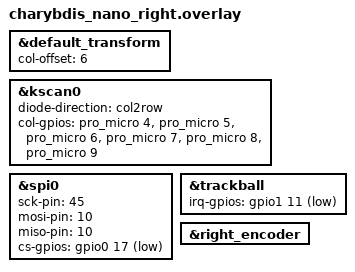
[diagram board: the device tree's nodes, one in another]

 
#include "charybdis_nano.dtsi"

&default_transform {
    col-offset = <6>;
};

&kscan0 {
    diode-direction = "col2row";
    col-gpios
        = <&pro_micro 4 (GPIO_ACTIVE_HIGH)> // COL0 
        , <&pro_micro 5 (GPIO_ACTIVE_HIGH)> // COL1 
        , <&pro_micro 6 (GPIO_ACTIVE_HIGH)> // COL2 
        , <&pro_micro 7 (GPIO_ACTIVE_HIGH)> // COL3 
	, <&pro_micro 8 (GPIO_ACTIVE_HIGH)> // COL1 
        , <&pro_micro 9 (GPIO_ACTIVE_HIGH)> // COL2 
    ;
    
};

// trackball bus
&spi0 {
	status = "okay"; //okay
	sck-pin = <45>;
	mosi-pin = <10>;
	miso-pin = <10>; // same as mosi (3-wire spi)
	cs-gpios = <&gpio0 17 GPIO_ACTIVE_LOW>;
};

&trackball {
	status = "okay"; //okay
	irq-gpios = <&gpio1 11 (GPIO_ACTIVE_LOW | GPIO_PULL_UP)>;
};


&right_encoder {
	status = "okay";
};

